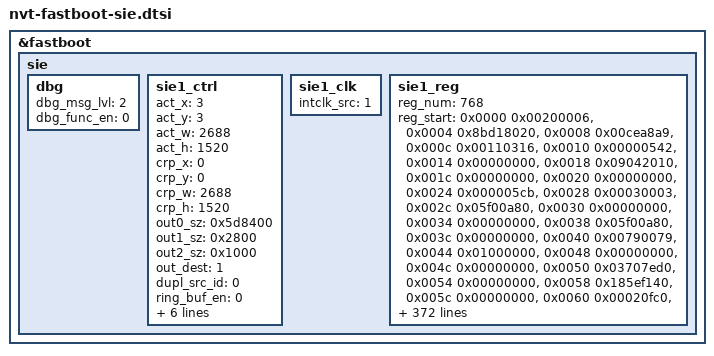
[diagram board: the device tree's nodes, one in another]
&fastboot {
	sie {
		dbg {
			dbg_msg_lvl = <2>;
			dbg_func_en = <0>;
		};

		sie1_ctrl {
			act_x = <3>;
			act_y = <3>;
			act_w = <2688>;
			act_h = <1520>;
			crp_x = <0>;
			crp_y = <0>;
			crp_w = <2688>;
			crp_h = <1520>;
			out0_sz = <0x5d8400>;
			out1_sz = <0x2800>;
			out2_sz = <0x1000>;
			out_dest = <1>;
			dupl_src_id = <0>;
			ring_buf_en = <0>;
			ring_buf_sz = <0x0>;
			sen_out_dest = <0x1>;
			shdr_en = <0>;
			ref_load_id = <0>;
			low_latency = <0>;
			one_buf_en = <0>;
		};

		sie1_clk {
			intclk_src = <1>;
		};

		sie1_reg {
			reg_num = <768>;
			reg_start = <0x0000 0x00200006>,
			<0x0004 0x8bd18020>,
			<0x0008 0x00cea8a9>,
			<0x000c 0x00110316>,
			<0x0010 0x00000542>,
			<0x0014 0x00000000>,
			<0x0018 0x09042010>,
			<0x001c 0x00000000>,
			<0x0020 0x00000000>,
			<0x0024 0x000005cb>,
			<0x0028 0x00030003>,
			<0x002c 0x05f00a80>,
			<0x0030 0x00000000>,
			<0x0034 0x00000000>,
			<0x0038 0x05f00a80>,
			<0x003c 0x00000000>,
			<0x0040 0x00790079>,
			<0x0044 0x01000000>,
			<0x0048 0x00000000>,
			<0x004c 0x00000000>,
			<0x0050 0x03707ed0>,
			<0x0054 0x00000000>,
			<0x0058 0x185ef140>,
			<0x005c 0x00000000>,
			<0x0060 0x00020fc0>,
			<0x0064 0x00000000>,
			<0x0068 0x18bc7540>,
			<0x006c 0x00000000>,
			<0x0070 0x00000000>,
			<0x0074 0x18bc9d40>,
			<0x0078 0x00000000>,
			<0x007c 0x01000000>,
			<0x0080 0x00000000>,
			<0x0084 0x00000000>,
			<0x0088 0x18bcad40>,
			<0x008c 0x00000000>,
			<0x0090 0x0f0fffff>,
			<0x0094 0x00000000>,
			<0x0098 0x09000000>,
			<0x009c 0x02000400>,
			<0x00a0 0x00000017>,
			<0x00a4 0x00000017>,
			<0x00a8 0x00000000>,
			<0x00ac 0x00000000>,
			<0x00b0 0x00000000>,
			<0x00b4 0x00000000>,
			<0x00b8 0x00000000>,
			<0x00bc 0x00000100>,
			<0x00c0 0x00000000>,
			<0x00c4 0x00000000>,
			<0x00c8 0x00000000>,
			<0x00cc 0x00000000>,
			<0x00d0 0x00000000>,
			<0x00d4 0x00000000>,
			<0x00d8 0x00000000>,
			<0x00dc 0x00000000>,
			<0x00e0 0x00000000>,
			<0x00e4 0x00000000>,
			<0x00e8 0x00000000>,
			<0x00ec 0x00000000>,
			<0x00f0 0x00000000>,
			<0x00f4 0x00000000>,
			<0x00f8 0x00000000>,
			<0x00fc 0x00000000>,
			<0x0100 0x00000000>,
			<0x0104 0x00000000>,
			<0x0108 0x00000000>,
			<0x010c 0x00000000>,
			<0x0110 0x00000000>,
			<0x0114 0x00000000>,
			<0x0118 0x00000000>,
			<0x011c 0x00000000>,
			<0x0120 0x00000000>,
			<0x0124 0x00000000>,
			<0x0128 0x00000000>,
			<0x012c 0x00000000>,
			<0x0130 0x00000000>,
			<0x0134 0x00000000>,
			<0x0138 0x00000000>,
			<0x013c 0x00000000>,
			<0x0140 0x00000000>,
			<0x0144 0x00000000>,
			<0x0148 0x00000000>,
			<0x014c 0x00000000>,
			<0x0150 0x00000000>,
			<0x0154 0x00080010>,
			<0x0158 0x0ac90618>,
			<0x015c 0x00000100>,
			<0x0160 0x00000000>,
			<0x0164 0x00000000>,
			<0x0168 0x00000000>,
			<0x016c 0x00000000>,
			<0x0170 0x00000000>,
			<0x0174 0x00000000>,
			<0x0178 0x00000000>,
			<0x017c 0x00000000>,
			<0x0180 0x00000000>,
			<0x0184 0x00000000>,
			<0x0188 0x00000000>,
			<0x018c 0x00000000>,
			<0x0190 0x00000000>,
			<0x0194 0x00000000>,
			<0x0198 0x00000000>,
			<0x019c 0x00000000>,
			<0x01a0 0x00000000>,
			<0x01a4 0x00000000>,
			<0x01a8 0x00000000>,
			<0x01ac 0x00000000>,
			<0x01b0 0x00000000>,
			<0x01b4 0x00800080>,
			<0x01b8 0x00800080>,
			<0x01bc 0x00010080>,
			<0x01c0 0x00000000>,
			<0x01c4 0x00000000>,
			<0x01c8 0x00000000>,
			<0x01cc 0x00000000>,
			<0x01d0 0x00000000>,
			<0x01d4 0x00000000>,
			<0x01d8 0x00000000>,
			<0x01dc 0x00000000>,
			<0x01e0 0x00000000>,
			<0x01e4 0x00000000>,
			<0x01e8 0x0000102c>,
			<0x01ec 0x00800080>,
			<0x01f0 0x00000080>,
			<0x01f4 0x00000000>,
			<0x01f8 0x00000000>,
			<0x01fc 0x00000000>,
			<0x0200 0x00000000>,
			<0x0204 0x00000000>,
			<0x0208 0x00000000>,
			<0x020c 0x00000000>,
			<0x0210 0x00000000>,
			<0x0214 0x00000000>,
			<0x0218 0x00000000>,
			<0x021c 0x00000000>,
			<0x0220 0x00000000>,
			<0x0224 0x07ed10d7>,
			<0x0228 0x05f00a80>,
			<0x022c 0x00000000>,
			<0x0230 0x00000000>,
			<0x0234 0x00000000>,
			<0x0238 0x00000000>,
			<0x023c 0x00000c0a>,
			<0x0240 0x00001f1f>,
			<0x0244 0x00000000>,
			<0x0248 0x00000000>,
			<0x024c 0x01800140>,
			<0x0250 0x08b12400>,
			<0x0254 0x1113c4c6>,
			<0x0258 0x16853530>,
			<0x025c 0x1b166d82>,
			<0x0260 0x1ed76dc7>,
			<0x0264 0x21b835fe>,
			<0x0268 0x2448da29>,
			<0x026c 0x26d97e52>,
			<0x0270 0x293a1e7a>,
			<0x0274 0x2b9ab2a0>,
			<0x0278 0x2ddb46c5>,
			<0x027c 0x2ffbd2e8>,
			<0x0280 0x31dc4f09>,
			<0x0284 0x33acc326>,
			<0x0288 0x356d3743>,
			<0x028c 0x372da35f>,
			<0x0290 0x38ce137b>,
			<0x0294 0x3a6e7b95>,
			<0x0298 0x3bfedfaf>,
			<0x029c 0x3d8f43c8>,
			<0x02a0 0x3effa3e0>,
			<0x02a4 0x000ffff7>,
			<0x02a8 0x00100100>,
			<0x02ac 0x00000c0a>,
			<0x02b0 0xc573df1f>,
			<0x02b4 0x00000000>,
			<0x02b8 0x00000000>,
			<0x02bc 0x00000000>,
			<0x02c0 0x00000000>,
			<0x02c4 0x00000000>,
			<0x02c8 0x00000000>,
			<0x02cc 0x00000000>,
			<0x02d0 0x00000000>,
			<0x02d4 0x00000000>,
			<0x02d8 0x00000000>,
			<0x02dc 0x00000000>,
			<0x02e0 0x00000000>,
			<0x02e4 0x00000000>,
			<0x02e8 0x00000000>,
			<0x02ec 0x00000000>,
			<0x02f0 0x00000000>,
			<0x02f4 0x00000000>,
			<0x02f8 0x00000000>,
			<0x02fc 0x00000000>,
			<0x0300 0x00260000>,
			<0x0304 0x071804ad>,
			<0x0308 0x06dd0dfc>,
			<0x030c 0x07250746>,
			<0x0310 0x04910509>,
			<0x0314 0x067d04bb>,
			<0x0318 0x065e06a5>,
			<0x031c 0x04890611>,
			<0x0320 0x039203de>,
			<0x0324 0x033a0339>,
			<0x0328 0x031a030e>,
			<0x032c 0x0373033b>,
			<0x0330 0x040b03a7>,
			<0x0334 0x048b045b>,
			<0x0338 0x04930458>,
			<0x033c 0x04c40517>,
			<0x0340 0x039f0425>,
			<0x0344 0x03ce039a>,
			<0x0348 0x042f0439>,
			<0x034c 0x03af03e1>,
			<0x0350 0x039903d1>,
			<0x0354 0x03ae037f>,
			<0x0358 0x02710332>,
			<0x035c 0x01a00213>,
			<0x0360 0x01950164>,
			<0x0364 0x015a0169>,
			<0x0368 0x01700164>,
			<0x036c 0x01750165>,
			<0x0370 0x0161015c>,
			<0x0374 0x01460156>,
			<0x0378 0x014c013c>,
			<0x037c 0x013a0145>,
			<0x0380 0x012d0130>,
			<0x0384 0x010d0110>,
			<0x0388 0x01350122>,
			<0x038c 0x00d40133>,
			<0x0390 0x001a0069>,
			<0x0394 0x00000003>,
			<0x0398 0x00000000>,
			<0x039c 0x00000000>,
			<0x03a0 0x00000000>,
			<0x03a4 0x00000000>,
			<0x03a8 0x00000000>,
			<0x03ac 0x00000000>,
			<0x03b0 0x00000000>,
			<0x03b4 0x00000000>,
			<0x03b8 0x00000000>,
			<0x03bc 0x00000000>,
			<0x03c0 0x00000000>,
			<0x03c4 0x00000000>,
			<0x03c8 0x00000000>,
			<0x03cc 0x00000000>,
			<0x03d0 0x00000000>,
			<0x03d4 0x00000000>,
			<0x03d8 0x00000000>,
			<0x03dc 0x00000000>,
			<0x03e0 0x00000000>,
			<0x03e4 0x00000000>,
			<0x03e8 0x00000000>,
			<0x03ec 0x00000000>,
			<0x03f0 0x00000000>,
			<0x03f4 0x00000000>,
			<0x03f8 0x00000000>,
			<0x03fc 0x00000000>,
			<0x0400 0x00000000>,
			<0x0404 0x00000000>,
			<0x0408 0x00000000>,
			<0x040c 0x00000000>,
			<0x0410 0x00000000>,
			<0x0414 0x00000000>,
			<0x0418 0x00000000>,
			<0x041c 0x00000000>,
			<0x0420 0x00000000>,
			<0x0424 0x00000000>,
			<0x0428 0x00000000>,
			<0x042c 0x00000000>,
			<0x0430 0x00000000>,
			<0x0434 0x00000000>,
			<0x0438 0x00000000>,
			<0x043c 0x00000000>,
			<0x0440 0x00000000>,
			<0x0444 0x00000000>,
			<0x0448 0x00000000>,
			<0x044c 0x00000000>,
			<0x0450 0x00000000>,
			<0x0454 0x00000000>,
			<0x0458 0x00000000>,
			<0x045c 0x00000000>,
			<0x0460 0x00000000>,
			<0x0464 0x00000000>,
			<0x0468 0x00000000>,
			<0x046c 0x00000000>,
			<0x0470 0x00000000>,
			<0x0474 0x00000000>,
			<0x0478 0x00000000>,
			<0x047c 0x00000000>,
			<0x0480 0x00000000>,
			<0x0484 0x00000000>,
			<0x0488 0x00000000>,
			<0x048c 0x00000000>,
			<0x0490 0x00000000>,
			<0x0494 0x00000000>,
			<0x0498 0x00000000>,
			<0x049c 0x00000000>,
			<0x04a0 0x00000000>,
			<0x04a4 0x00000000>,
			<0x04a8 0x00000000>,
			<0x04ac 0x00000000>,
			<0x04b0 0x00000000>,
			<0x04b4 0x00000000>,
			<0x04b8 0x00000000>,
			<0x04bc 0x00000000>,
			<0x04c0 0x00000000>,
			<0x04c4 0x00000000>,
			<0x04c8 0x00000000>,
			<0x04cc 0x00000000>,
			<0x04d0 0x00000000>,
			<0x04d4 0x00000000>,
			<0x04d8 0x00000000>,
			<0x04dc 0x00000000>,
			<0x04e0 0x00000000>,
			<0x04e4 0x00000000>,
			<0x04e8 0x00000000>,
			<0x04ec 0x00000000>,
			<0x04f0 0x00000000>,
			<0x04f4 0x00000000>,
			<0x04f8 0x00000000>,
			<0x04fc 0x00000000>,
			<0x0500 0x00000000>,
			<0x0504 0x00000000>,
			<0x0508 0x00000000>,
			<0x050c 0x00000000>,
			<0x0510 0x00000000>,
			<0x0514 0x00000000>,
			<0x0518 0x00000000>,
			<0x051c 0x00000000>,
			<0x0520 0x00000000>,
			<0x0524 0x00000000>,
			<0x0528 0x00000000>,
			<0x052c 0x00000000>,
			<0x0530 0x00000000>,
			<0x0534 0x00000000>,
			<0x0538 0x00000000>,
			<0x053c 0x00000000>,
			<0x0540 0x00000000>,
			<0x0544 0x00000000>,
			<0x0548 0x00000000>,
			<0x054c 0x00000000>,
			<0x0550 0x00000000>,
			<0x0554 0x00000000>,
			<0x0558 0x00000000>,
			<0x055c 0x00000000>,
			<0x0560 0x00000000>,
			<0x0564 0x00000000>,
			<0x0568 0x00000000>,
			<0x056c 0x00000000>,
			<0x0570 0x00000000>,
			<0x0574 0x00000000>,
			<0x0578 0x00000000>,
			<0x057c 0x00000000>,
			<0x0580 0x00000000>,
			<0x0584 0x00000000>,
			<0x0588 0x00000000>,
			<0x058c 0x00000000>,
			<0x0590 0x00000000>,
			<0x0594 0x00000000>,
			<0x0598 0x00000000>,
			<0x059c 0x00000000>,
			<0x05a0 0x00000000>,
			<0x05a4 0x00000000>,
			<0x05a8 0x00000000>,
			<0x05ac 0x00000000>,
			<0x05b0 0x00000000>,
			<0x05b4 0x00000000>,
			<0x05b8 0x00000000>,
			<0x05bc 0x00000000>,
			<0x05c0 0x00000000>,
			<0x05c4 0x00000000>,
			<0x05c8 0x00000000>,
			<0x05cc 0x00000000>,
			<0x05d0 0x00000000>,
			<0x05d4 0x00000000>,
			<0x05d8 0x00000000>,
			<0x05dc 0x00000000>,
			<0x05e0 0x00000000>,
			<0x05e4 0x00000000>,
			<0x05e8 0x00000000>,
			<0x05ec 0x00000000>,
			<0x05f0 0x00000000>,
			<0x05f4 0x00000000>,
			<0x05f8 0x00000000>,
			<0x05fc 0x00000000>,
			<0x0600 0x00000000>,
			<0x0604 0x00000000>,
			<0x0608 0x00000000>,
			<0x060c 0x00000000>,
			<0x0610 0x00000000>,
			<0x0614 0x00000000>,
			<0x0618 0x00000000>,
			<0x061c 0x00000000>,
			<0x0620 0x00000000>,
			<0x0624 0x00000000>,
			<0x0628 0x00000000>,
			<0x062c 0x00000000>,
			<0x0630 0x00000000>,
			<0x0634 0x00000000>,
			<0x0638 0x00000000>,
			<0x063c 0x00000000>,
			<0x0640 0x00000000>,
			<0x0644 0x00000000>,
			<0x0648 0x00000000>,
			<0x064c 0x00000000>,
			<0x0650 0x00000000>,
			<0x0654 0x00000000>,
			<0x0658 0x00000000>,
			<0x065c 0x00000000>,
			<0x0660 0x00000000>,
			<0x0664 0x00000000>,
			<0x0668 0x00000000>,
			<0x066c 0x00000000>,
			<0x0670 0x00000000>,
			<0x0674 0x00000000>,
			<0x0678 0x00000000>,
			<0x067c 0x00000000>,
			<0x0680 0x00000000>,
			<0x0684 0x00000000>,
			<0x0688 0x00000000>,
			<0x068c 0x00000000>,
			<0x0690 0x00000000>,
			<0x0694 0x00000000>,
			<0x0698 0x00000000>,
			<0x069c 0x00000000>,
			<0x06a0 0x00000000>,
			<0x06a4 0x00000000>,
			<0x06a8 0x00000000>,
			<0x06ac 0x00000000>,
			<0x06b0 0x00000000>,
			<0x06b4 0x00000000>,
			<0x06b8 0x00000000>,
			<0x06bc 0x00000000>,
			<0x06c0 0x00000000>,
			<0x06c4 0x00000000>,
			<0x06c8 0x00000000>,
			<0x06cc 0x00000000>,
			<0x06d0 0x00000000>,
			<0x06d4 0x00000000>,
			<0x06d8 0x00000000>,
			<0x06dc 0x00000000>,
			<0x06e0 0x00000000>,
			<0x06e4 0x00000000>,
			<0x06e8 0x00000000>,
			<0x06ec 0x00000000>,
			<0x06f0 0x00000000>,
			<0x06f4 0x00000000>,
			<0x06f8 0x00000000>,
			<0x06fc 0x00000000>,
			<0x0700 0x00000000>,
			<0x0704 0x00000000>,
			<0x0708 0x00000000>,
			<0x070c 0x00000000>,
			<0x0710 0x00000000>,
			<0x0714 0x00000000>,
			<0x0718 0x00000000>,
			<0x071c 0x00000000>,
			<0x0720 0x00000000>,
			<0x0724 0x00000000>,
			<0x0728 0x00000000>,
			<0x072c 0x00000000>,
			<0x0730 0x00000000>,
			<0x0734 0x00000000>,
			<0x0738 0x00000000>,
			<0x073c 0x00000000>,
			<0x0740 0x00000000>,
			<0x0744 0x00000000>,
			<0x0748 0x00000000>,
			<0x074c 0x00000000>,
			<0x0750 0x00000000>,
			<0x0754 0x00000000>,
			<0x0758 0x00000000>,
			<0x075c 0x00000000>,
			<0x0760 0x00000000>,
			<0x0764 0x00000000>,
			<0x0768 0x00000000>,
			<0x076c 0x00000000>,
			<0x0770 0x00000000>,
			<0x0774 0x00000000>,
			<0x0778 0x00000000>,
			<0x077c 0x00000000>,
			<0x0780 0x00000000>,
			<0x0784 0x00000000>,
			<0x0788 0x00000000>,
			<0x078c 0x00000000>,
			<0x0790 0x00000000>,
			<0x0794 0x00000000>,
			<0x0798 0x00000000>,
			<0x079c 0x00000000>,
			<0x07a0 0x00000000>,
			<0x07a4 0x00000000>,
			<0x07a8 0x00000000>,
			<0x07ac 0x00000000>,
			<0x07b0 0x00000000>,
			<0x07b4 0x00000000>,
			<0x07b8 0x00000000>,
			<0x07bc 0x00000000>,
			<0x07c0 0x05f305f3>,
			<0x07c4 0x98d2c42c>,
			<0x07c8 0x98fbb950>,
			<0x07cc 0x98fbb950>,
			<0x07d0 0x00000000>,
			<0x07d4 0x98fbb950>,
			<0x07d8 0x00000000>,
			<0x07dc 0x00000000>,
			<0x07e0 0x13747fd0>,
			<0x07e4 0x05f405f4>,
			<0x07e8 0x00000542>,
			<0x07ec 0x00000000>,
			<0x07f0 0x0028a2ac>,
			<0x07f4 0x0000047b>,
			<0x07f8 0x001a980d>,
			<0x07fc 0x000d7300>,
			<0x0800 0x00000000>,
			<0x0804 0x00000000>,
			<0x0808 0x00000000>,
			<0x080c 0x00000000>,
			<0x0810 0x00000000>,
			<0x0814 0x00000000>,
			<0x0818 0x00000000>,
			<0x081c 0x00000000>,
			<0x0820 0x00000000>,
			<0x0824 0x00000000>,
			<0x0828 0x00000000>,
			<0x082c 0x00000000>,
			<0x0830 0x00000000>,
			<0x0834 0x00000000>,
			<0x0838 0x00000000>,
			<0x083c 0x00000000>,
			<0x0840 0x00000000>,
			<0x0844 0x00000000>,
			<0x0848 0x00000000>,
			<0x084c 0x00000000>,
			<0x0850 0x00000000>,
			<0x0854 0x00000000>,
			<0x0858 0x00000000>,
			<0x085c 0x00000000>,
			<0x0860 0x00000000>,
			<0x0864 0x00000000>,
			<0x0868 0x00000000>,
			<0x086c 0x00000000>,
			<0x0870 0x00000000>,
			<0x0874 0x00000000>,
			<0x0878 0x00000000>,
			<0x087c 0x00000000>,
			<0x0880 0x00000000>,
			<0x0884 0x00000000>,
			<0x0888 0x00000000>,
			<0x088c 0x00000000>,
			<0x0890 0x00000000>,
			<0x0894 0x00000000>,
			<0x0898 0x00000000>,
			<0x089c 0x00000000>,
			<0x08a0 0x00000000>,
			<0x08a4 0x00000000>,
			<0x08a8 0x00000000>,
			<0x08ac 0x00000000>,
			<0x08b0 0x00000000>,
			<0x08b4 0x00000000>,
			<0x08b8 0x00000000>,
			<0x08bc 0x00000000>,
			<0x08c0 0x00000000>,
			<0x08c4 0x00000000>,
			<0x08c8 0x00000000>,
			<0x08cc 0x00000000>,
			<0x08d0 0x00000000>,
			<0x08d4 0x00000000>,
			<0x08d8 0x00000000>,
			<0x08dc 0x00000000>,
			<0x08e0 0x00000000>,
			<0x08e4 0x00000000>,
			<0x08e8 0x00000000>,
			<0x08ec 0x00000000>,
			<0x08f0 0x00000000>,
			<0x08f4 0x00000000>,
			<0x08f8 0x00000000>,
			<0x08fc 0x00000000>,
			<0x0900 0x00000000>,
			<0x0904 0x00000000>,
			<0x0908 0x00000000>,
			<0x090c 0x00000000>,
			<0x0910 0x00000000>,
			<0x0914 0x00000000>,
			<0x0918 0x00000000>,
			<0x091c 0x00000000>,
			<0x0920 0x00000000>,
			<0x0924 0x00000000>,
			<0x0928 0x00000000>,
			<0x092c 0x00000000>,
			<0x0930 0x00000000>,
			<0x0934 0x00000000>,
			<0x0938 0x00000000>,
			<0x093c 0x00000000>,
			<0x0940 0x00000000>,
			<0x0944 0x00000000>,
			<0x0948 0x00000000>,
			<0x094c 0x00000000>,
			<0x0950 0x00000000>,
			<0x0954 0x00000000>,
			<0x0958 0x00000000>,
			<0x095c 0x00000000>,
			<0x0960 0x00000000>,
			<0x0964 0x00000000>,
			<0x0968 0x00000000>,
			<0x096c 0x00000000>,
			<0x0970 0x00000000>,
			<0x0974 0x00000000>,
			<0x0978 0x00000000>,
			<0x097c 0x00000000>,
			<0x0980 0x00000000>,
			<0x0984 0x00000000>,
			<0x0988 0x00000000>,
			<0x098c 0x00000000>,
			<0x0990 0x00000000>,
			<0x0994 0x00000000>,
			<0x0998 0x00000000>,
			<0x099c 0x00000000>,
			<0x09a0 0x00000000>,
			<0x09a4 0x00000000>,
			<0x09a8 0x00000000>,
			<0x09ac 0x00000000>,
			<0x09b0 0x00000000>,
			<0x09b4 0x00000000>,
			<0x09b8 0x00000000>,
			<0x09bc 0x00000000>,
			<0x09c0 0x00000000>,
			<0x09c4 0x00000000>,
			<0x09c8 0x00000000>,
			<0x09cc 0x00000000>,
			<0x09d0 0x00000000>,
			<0x09d4 0x00000000>,
			<0x09d8 0x00000000>,
			<0x09dc 0x00000000>,
			<0x09e0 0x00000000>,
			<0x09e4 0x00000000>,
			<0x09e8 0x00000000>,
			<0x09ec 0x00000000>,
			<0x09f0 0x00000000>,
			<0x09f4 0x00000000>,
			<0x09f8 0x00000000>,
			<0x09fc 0x00000000>,
			<0x0a00 0x00000000>,
			<0x0a04 0x00000000>,
			<0x0a08 0x00000000>,
			<0x0a0c 0x00000000>,
			<0x0a10 0x0c080400>,
			<0x0a14 0x1c181410>,
			<0x0a18 0x61442b13>,
			<0x0a1c 0x00000000>,
			<0x0a20 0x00000000>,
			<0x0a24 0x00000000>,
			<0x0a28 0x00000000>,
			<0x0a2c 0x00000000>,
			<0x0a30 0x00000000>,
			<0x0a34 0x00000000>,
			<0x0a38 0x00000000>,
			<0x0a3c 0x00000000>,
			<0x0a40 0x00000000>,
			<0x0a44 0x00000000>,
			<0x0a48 0x00000000>,
			<0x0a4c 0x00000000>,
			<0x0a50 0x00000000>,
			<0x0a54 0x00000000>,
			<0x0a58 0x00000000>,
			<0x0a5c 0x00000000>,
			<0x0a60 0x00000000>,
			<0x0a64 0x00000000>,
			<0x0a68 0x00000000>,
			<0x0a6c 0x00000000>,
			<0x0a70 0x00000000>,
			<0x0a74 0x00000000>,
			<0x0a78 0x00000000>,
			<0x0a7c 0x00000000>,
			<0x0a80 0x00000000>,
			<0x0a84 0x00000000>,
			<0x0a88 0x00000000>,
			<0x0a8c 0x00000000>,
			<0x0a90 0x00000000>,
			<0x0a94 0x00000000>,
			<0x0a98 0x00000000>,
			<0x0a9c 0x00000000>,
			<0x0aa0 0x00000000>,
			<0x0aa4 0x00000000>,
			<0x0aa8 0x00000000>,
			<0x0aac 0x00000000>,
			<0x0ab0 0x00000000>,
			<0x0ab4 0x00000000>,
			<0x0ab8 0x00000000>,
			<0x0abc 0x00000000>,
			<0x0ac0 0x00000000>,
			<0x0ac4 0x00000000>,
			<0x0ac8 0x00000000>,
			<0x0acc 0x00000000>,
			<0x0ad0 0x00000000>,
			<0x0ad4 0x00000000>,
			<0x0ad8 0x00000000>,
			<0x0adc 0x00000000>,
			<0x0ae0 0x00000000>,
			<0x0ae4 0x00000000>,
			<0x0ae8 0x00000000>,
			<0x0aec 0x00000000>,
			<0x0af0 0x00000000>,
			<0x0af4 0x00000000>,
			<0x0af8 0x00000000>,
			<0x0afc 0x00000000>,
			<0x0b00 0x00000000>,
			<0x0b04 0x00000000>,
			<0x0b08 0x00000000>,
			<0x0b0c 0x00000000>,
			<0x0b10 0x00000000>,
			<0x0b14 0x00000000>,
			<0x0b18 0x00000000>,
			<0x0b1c 0x00000000>,
			<0x0b20 0x00000000>,
			<0x0b24 0x00000000>,
			<0x0b28 0x00000000>,
			<0x0b2c 0x00000000>,
			<0x0b30 0x00000000>,
			<0x0b34 0x00000000>,
			<0x0b38 0x00000000>,
			<0x0b3c 0x00000000>,
			<0x0b40 0x00000000>,
			<0x0b44 0x00000000>,
			<0x0b48 0x00000000>,
			<0x0b4c 0x00000000>,
			<0x0b50 0x00000000>,
			<0x0b54 0x00000000>,
			<0x0b58 0x00000000>,
			<0x0b5c 0x00000000>,
			<0x0b60 0x00000000>,
			<0x0b64 0x00000000>,
			<0x0b68 0x00000000>,
			<0x0b6c 0x00000000>,
			<0x0b70 0x00000000>,
			<0x0b74 0x00000000>,
			<0x0b78 0x00000000>,
			<0x0b7c 0x00000000>,
			<0x0b80 0x00000000>,
			<0x0b84 0x00000000>,
			<0x0b88 0x00000000>,
			<0x0b8c 0x00000000>,
			<0x0b90 0x00000000>,
			<0x0b94 0x00000000>,
			<0x0b98 0x00000000>,
			<0x0b9c 0x00000000>,
			<0x0ba0 0x00000000>,
			<0x0ba4 0x00000000>,
			<0x0ba8 0x00000000>,
			<0x0bac 0x00000000>,
			<0x0bb0 0x00000000>,
			<0x0bb4 0x00000000>,
			<0x0bb8 0x00000000>,
			<0x0bbc 0x00000000>,
			<0x0bc0 0x00000000>,
			<0x0bc4 0x00000000>,
			<0x0bc8 0x00000000>,
			<0x0bcc 0x00000000>,
			<0x0bd0 0x00000000>,
			<0x0bd4 0x00000000>,
			<0x0bd8 0x00000000>,
			<0x0bdc 0x00000000>,
			<0x0be0 0x00000000>,
			<0x0be4 0x00000000>,
			<0x0be8 0x00000000>,
			<0x0bec 0x00000000>,
			<0x0bf0 0x00000000>,
			<0x0bf4 0x00000000>,
			<0x0bf8 0x00000000>,
			<0x0bfc 0x00000000>,
			<0x0c00 0x00000000>;
		};

	};
};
